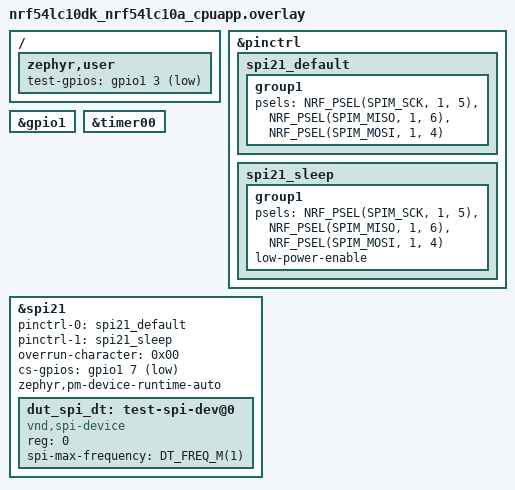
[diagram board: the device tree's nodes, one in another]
/*
 * Copyright (c) 2026 Nordic Semiconductor ASA
 *
 * SPDX-License-Identifier: LicenseRef-Nordic-5-Clause
 */

/* Test requires wire connection:
 *  - SPIM_MOSI with test-gpios -> P1.03 - P1.04.
 * (Pins chosen to avoid DK buttons and LEDs on nRF54LC10 DK.)
 */

/ {
	zephyr,user {
		test-gpios = <&gpio1 3 GPIO_ACTIVE_LOW>;
	};
};

&pinctrl {
	spi21_default: spi21_default {
		group1 {
			psels = <NRF_PSEL(SPIM_SCK, 1, 5)>,
				<NRF_PSEL(SPIM_MISO, 1, 6)>,
				<NRF_PSEL(SPIM_MOSI, 1, 4)>;
		};
	};

	spi21_sleep: spi21_sleep {
		group1 {
			psels = <NRF_PSEL(SPIM_SCK, 1, 5)>,
				<NRF_PSEL(SPIM_MISO, 1, 6)>,
				<NRF_PSEL(SPIM_MOSI, 1, 4)>;
			low-power-enable;
		};
	};
};

&gpio1 {
	status = "okay";
};

&timer00 {
	status = "okay";
};

&spi21 {
	status = "okay";
	pinctrl-0 = <&spi21_default>;
	pinctrl-1 = <&spi21_sleep>;
	pinctrl-names = "default", "sleep";
	overrun-character = <0x00>;
	cs-gpios = <&gpio1 7 GPIO_ACTIVE_LOW>;
	zephyr,pm-device-runtime-auto;

	dut_spi_dt: test-spi-dev@0 {
		compatible = "vnd,spi-device";
		reg = <0>;
		spi-max-frequency = <DT_FREQ_M(1)>;
	};
};
